# D1H.pdf register map
Vendor: Allwinner; Series: D1H.pdf; File version: 0.1
CPU: XuanTie C906 RISC-V CPU 0, little endian, MPU, FPU, double-precision FPU, 0 interrupt priority bits
Registers are 32-bit, read-write, reset 0x0 unless marked. A register's access mark holds for its fields unless they carry their own. Offsets are from the block's base; [hi:lo] are bit positions; lines under a group give offsets from that group; {n}, {i} and the like mark numbered series; 'fields as' and 'values as' point back to an identical list.

## TVD0
Base 0x05C01000
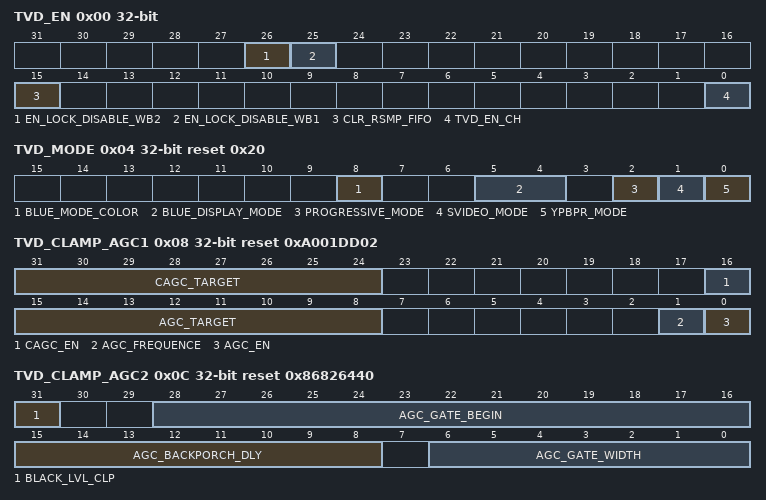
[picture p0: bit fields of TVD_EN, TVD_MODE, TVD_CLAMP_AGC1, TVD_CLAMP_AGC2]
0x00 TVD_EN — TVD MODULE CONTROL Register
  [26] EN_LOCK_DISABLE_WB2 — Enable Lock Disable WB2
  [25] EN_LOCK_DISABLE_WB1 — Enable Lock Disable WB1
  [15] CLR_RSMP_FIFO — Clear Resample FIFO 0: Release 1: Clear Set 0x1 then 0x0 to reset resample FIFO.
    0=Release; 1=Clear Set 0x1 then 0x0 to reset resample FIFO
  [0] TVD_EN_CH — TVD Enable CH 0: Disable 1: Enable
    0=Disable; 1=Enable
0x04 TVD_MODE reset 0x20 — TVD MODE CONTROL Register
  [8] BLUE_MODE_COLOR — Blue Mode Color 0: Blue 1: Black
    0=Blue; 1=Black
  [5:4] BLUE_DISPLAY_MODE — Blue Display Mode 00 : Disabled 01 : Enabled 10 : Auto 11 : Reserved
  [2] PROGRESSIVE_MODE — Progressive Mode 0: Interlace mode 1: Progressive mode
    0=Interlace_mode; 1=Progressive_mode
  [1] SVIDEO_MODE — Svideo Mode 0 : CVBS 1 : S-Video
  [0] YPBPR_MODE — Ypbpr Mode 0 : Disable the component input 1 : Enable the component input
0x08 TVD_CLAMP_AGC1 reset 0xA001DD02 — TVD CLAMP & AGC CONTROL Register1
  [31:24] CAGC_TARGET — Cagc Target These bits set the chroma AGC target
  [16] CAGC_EN — Cagc Enable 0 : OFF 1 : ON
  [15:8] AGC_TARGET — Auto Gain Control Target When AGC_EN = 1 , the AGC_TARGET is used to directly digital AGC circuit. When AGC_EN = 0 , the AGC_TARGET is used to directly drive the analog PGA. (64 represents 1x, 32 represents 0.5x).
  [1] AGC_FREQUENCE — Auto Gain Control Freqence 0 : AGC gain update once per line 1 : AGC gain update once per frame
  [0] AGC_EN — Auto Gain Control Enable 0 : AGC disable 1 : AGC enable
0x0C TVD_CLAMP_AGC2 reset 0x86826440 — TVD CLAMP & AGC CONTROL Register2
  [31] BLACK_LVL_CLP — Black Level Clamp 0: subtraction 0 1: subtraction 16
    0=subtraction_0; 1=subtraction_16
  [28:16] AGC_GATE_BEGIN — AGC Gate Begin Count from hsync to the next line AGC gate
  [15:8] AGC_BACKPORCH_DLY — AGC Backporch Delay Count from sync tip to back porch gate
  [6:0] AGC_GATE_WIDTH
0x10 TVD_HLOCK1 reset 0x20000000 — TVD HLOCK CONTROL Register1
  [31:0] H_SAMPLE_STEP — H Sample Step H_SAMPLE_STEP = Fout/Fin X 2^30
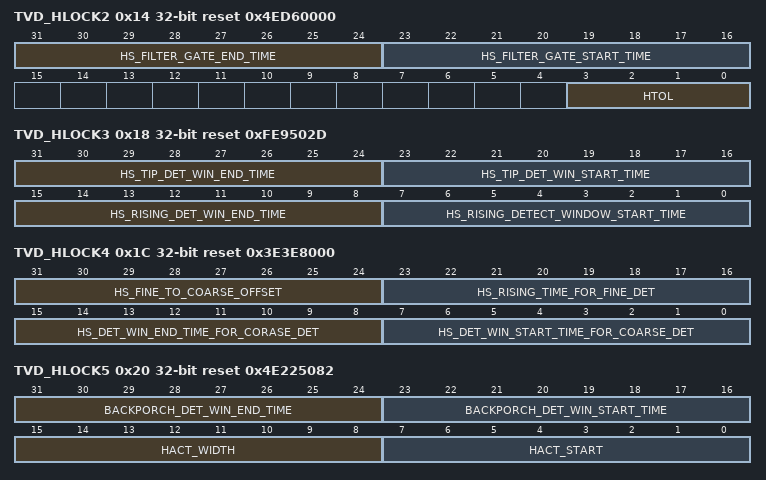
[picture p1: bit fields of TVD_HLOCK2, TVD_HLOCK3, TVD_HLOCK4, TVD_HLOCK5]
0x14 TVD_HLOCK2 reset 0x4ED60000 — TVD HLOCK CONTROL Register2
  [31:24] HS_FILTER_GATE_END_TIME — HSYNC Filter Gate End Time These bits specify the end of the horizontal-blank-interval window. Default/Hex = 78
  [23:16] HS_FILTER_GATE_START_TIME — HSYNC Filter Gate Start Time These bits specify the beginning of the horizontal-blank-interval window. Default/Hex = -42
  [3:0] HTOL — Horizontal Total Pixels Per Line 0: 858 1: 864 2~7: Reserved
0x18 TVD_HLOCK3 reset 0xFE9502D — TVD HLOCK CONTROL Register3
  [31:24] HS_TIP_DET_WIN_END_TIME — HSYNC Tip Detect Window End Time
  [23:16] HS_TIP_DET_WIN_START_TIME — HSYNC Tip Detect Window Start Time
  [15:8] HS_RISING_DET_WIN_END_TIME — HSYNC Rising Detect Window End Time
  [7:0] HS_RISING_DETECT_WINDOW_START_TIME — HSYNC Rising Detect Window Start Time
0x1C TVD_HLOCK4 reset 0x3E3E8000 — TVD HLOCK CONTROL Register4
  [31:24] HS_FINE_TO_COARSE_OFFSET — HSYNC Fine To Coarse Offset
  [23:16] HS_RISING_TIME_FOR_FINE_DET — HSYNC Rising Time For Fine Detect
  [15:8] HS_DET_WIN_END_TIME_FOR_CORASE_DET — HSYNC Detect Window End Time For Corase Detect
  [7:0] HS_DET_WIN_START_TIME_FOR_COARSE_DET — HSYNC Detect Window Start Time For Coarse Detect
0x20 TVD_HLOCK5 reset 0x4E225082 — TVD HLOCK CONTROL Register5
  [31:24] BACKPORCH_DET_WIN_END_TIME — Backporch Detect Window End Time
  [23:16] BACKPORCH_DET_WIN_START_TIME — Backporch Detect Window Start Time
  [15:8] HACT_WIDTH — Hactive Width
  [7:0] HACT_START — Hactive Start
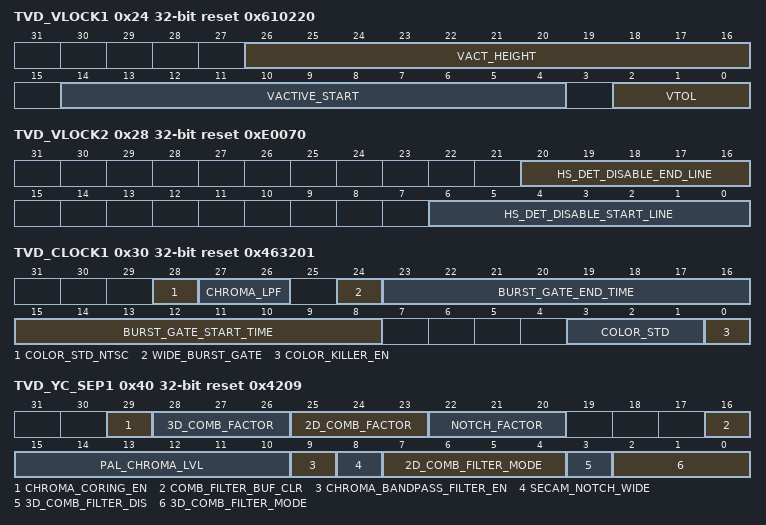
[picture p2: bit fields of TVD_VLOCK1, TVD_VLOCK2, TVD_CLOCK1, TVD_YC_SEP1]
0x24 TVD_VLOCK1 reset 0x610220 — TVD VLOCK CONTROL Register1
  [26:16] VACT_HEIGHT — Vactive Height
  [14:4] VACTIVE_START — VACT START
  [2:0] VTOL — Vertical Total Line Per Frame 0 : 525 line 1 : 625 line
0x28 TVD_VLOCK2 reset 0xE0070 — TVD VLOCK CONTROL Register2
  [20:16] HS_DET_DISABLE_END_LINE — Hsync Detector Disable End Line
  [6:0] HS_DET_DISABLE_START_LINE — Hsync Dectector Disable Start Line
0x30 TVD_CLOCK1 reset 0x463201 — TVD CHROMA LOCK CONTROL Register1
  [28] COLOR_STD_NTSC — Color Standard Ntsc 0: NTSC358 1: NTSC443 Only valid when COLOR_STD set as NTSC
    0=NTSC358; 1=NTSC443 (NTSC443 Only valid when COLOR_STD set as NTSC)
  [27:26] CHROMA_LPF — CHROMA Low Pass Filter 00: Narrow 01: Middle 10: Wide 11: Reserved
    0=Narrow; 1=Middle; 2=Wide
  [24] WIDE_BURST_GATE — Wide Burst_Gate 0: Narrow burst gate 1: Wide burst gate
    0=Narrow burst gate; 1=Wide burst gate
  [23:16] BURST_GATE_END_TIME
  [15:8] BURST_GATE_START_TIME
  [3:1] COLOR_STD — COLOR Standard 000: NTSC 001: PAL (I,B,G,H,D,N) 010: PAL (M) 011: PAL (CN) 100: SECAM
  [0] COLOR_KILLER_EN — Color Killer Enable 1: Disable color when chroma unlock
    1=Disable color when chroma unlock
0x34 TVD_CLOCK2 reset 0x21F07C1F — TVD CHROMA LOCK CONTROL Register2
  [31:0] C_SAMPLE_STEP — C Sample Step C_SAMPLE_STEP = Fsc/Fin X 2^30
0x40 TVD_YC_SEP1 reset 0x4209 — TVD YC SEPERATION CONROL Register1
  [29] CHROMA_CORING_EN — Chroma Coring Enable
  [28:26] 3D_COMB_FACTOR
  [25:23] 2D_COMB_FACTOR
  [22:20] NOTCH_FACTOR
  [16] COMB_FILTER_BUF_CLR — Comb Filter Buffer Clear 0: Not clear 1: Clear
    0=Not_clear; 1=Clear
  [15:10] PAL_CHROMA_LVL — PAL Chroma Level Chroma level threshold for chroma comb filter select
  [9] CHROMA_BANDPASS_FILTER_EN — Chroma Bandpass Filter Enable 0: Disable 1: Enable
    0=Disable; 1=Enable
  [8] SECAM_NOTCH_WIDE — Notch bandwidth 0 : Narrow 1 : Wide
  [7:4] 2D_COMB_FILTER_MODE — 2D Comb Filter Mode For NTSC: 0000: 2D comb 0001~0010: Reserved 0011: 1D comb 0100~1000: Reserved For PAL: 0000:2D comb filter1 0001: 1D comb filter1 0010: 2D comb filter2 0011: 1D comb filter2 0100: 1D comb filter3 0101: Reserved 0110: 2D comb filter3 0111~1000:Reserved
    0=_2D_comb_0001_tilde_0010 (2D comb 0001~0010: Reserved); 3=_1D_comb_0100_tilde_1000 (1D comb 0100~1000: Reserved For PAL: 0000:2D comb filter1); 1=_1D_comb_filter1; 2=_2D_comb_filter2; 3=_1D_comb_filter2; 4=_1D_comb_filter3; 6=2D comb filter3 0111~1000:Reserved
  [3] 3D_COMB_FILTER_DIS — 3D Comb Filter Disable 0: Enable 3D comb filter 1: Disable 3D comb filter
    0=Enable 3D comb filter; 1=Disable 3D comb filter
  [2:0] 3D_COMB_FILTER_MODE — 3D Comb_Filter Mode 000: 2D mode 001: 3D YC separation mode1 010~011: reserved 0100: 3D YC separation mode2
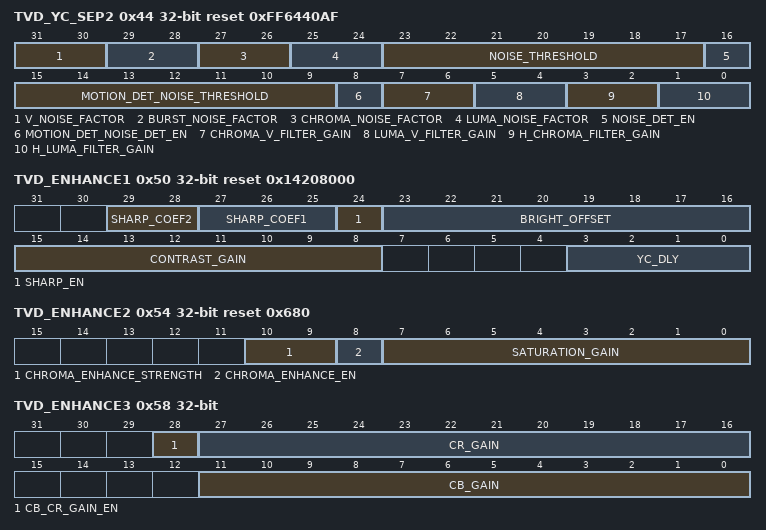
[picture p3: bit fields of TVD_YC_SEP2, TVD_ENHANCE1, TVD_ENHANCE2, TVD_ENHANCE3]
0x44 TVD_YC_SEP2 reset 0xFF6440AF — TVD YC SEPERATION CONROL Register2
  [31:30] V_NOISE_FACTOR — Vertical Noise Factor
  [29:28] BURST_NOISE_FACTOR
  [27:26] CHROMA_NOISE_FACTOR
  [25:24] LUMA_NOISE_FACTOR
  [23:17] NOISE_THRESHOLD
  [16] NOISE_DET_EN — Noise Detect Enable
  [15:9] MOTION_DET_NOISE_THRESHOLD — Motion Detect Noise Threshold
  [8] MOTION_DET_NOISE_DET_EN — Motion Detect Noise Detect Enable
  [7:6] CHROMA_V_FILTER_GAIN — Chroma Vertical Filter Gain
  [5:4] LUMA_V_FILTER_GAIN — Luma Vertical Filter Gain
  [3:2] H_CHROMA_FILTER_GAIN — Horizontal Chroma Filter Gain
  [1:0] H_LUMA_FILTER_GAIN — Horizontal Luma Filter Gain
0x50 TVD_ENHANCE1 reset 0x14208000 — TVD ENHANCEMENT CONTROL Register1
  [29:28] SHARP_COEF2
  [27:25] SHARP_COEF1 — Sharp Coef1 Ysharp = Y + YH *(SHARP_COEF1/ SHARP_COEF2)
  [24] SHARP_EN — Sharp Enable 0: Disable 1: Enable
    0=Disable; 1=Enable
  [23:16] BRIGHT_OFFSET — Bright Offset Set 0x00, brightness offset is -32; Set 0x20, brightness offset is 0. Set 0xFF, brightness offset is max.
  [15:8] CONTRAST_GAIN — Contrast Gain Set 0x00, contrast gain is min ; Set 0x80, contrast gain is 1. Set 0xFF, contrast gain is max.
  [3:0] YC_DLY — YC Delay 0000: Y and C no delay 0001: Y delay 1 cycle to C 0010: Y delay 2 cycle to C 0011: Y delay 3 cycle to C 0100: Y delay 4 cycle to C 0101: Y delay 5 cycle to C 0110: Y delay 6 cycle to C 0111: Y delay 7 cycle to C 1000: Reserved 1001: Reserved 1010: Reserved 1011: C delay 5 cycle to Y 1100: C delay 4 cycle to Y 1101: C delay 3 cycle to Y 1110: C delay 2 cycle to Y 1111: C delay 1 cycle to Y
    0=Y and C no delay; {v}=Y delay {v} cycle to C (v=1..7); 11=C delay 5 cycle to Y; 12=C delay 4 cycle to Y; 13=C delay 3 cycle to Y; 14=C delay 2 cycle to Y; 15=C delay 1 cycle to Y
0x54 TVD_ENHANCE2 reset 0x680 — TVD ENHANCEMENT CONTROL Register2
  [10:9] CHROMA_ENHANCE_STRENGTH — Chroma Enhance Strength 00: Mild 01: Low 10: Middle 11: High
    0=Mild; 1=Low; 2=Middle; 3=High
  [8] CHROMA_ENHANCE_EN — Chroma Enhance Enable 0: Disable 1: Enable
    0=Disable; 1=Enable
  [7:0] SATURATION_GAIN — Saturation Gain Set 0x00, saturation gain is min ; Set 0x80, saturation gain is 1. Set 0xFF, saturation gain is max.
0x58 TVD_ENHANCE3 — TVD ENHANCEMENT CONTROL Register3
  [28] CB_CR_GAIN_EN — Cb Cr Gain Enable
  [27:16] CR_GAIN
  [11:0] CB_GAIN
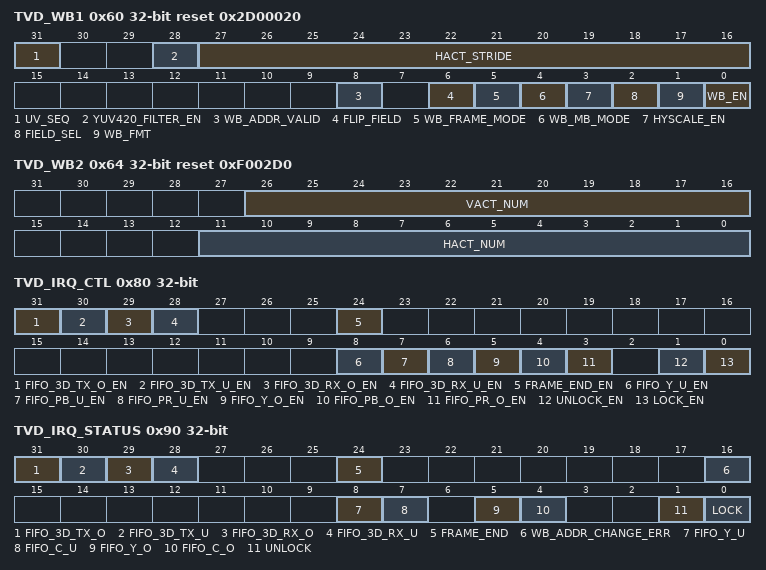
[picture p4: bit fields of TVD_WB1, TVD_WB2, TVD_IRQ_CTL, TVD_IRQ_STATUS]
0x60 TVD_WB1 reset 0x2D00020 — TVD WB DMA CONTROL Register1
  [31] UV_SEQ — UV Sequence 0: UVUV 1: VUVU
    0=UVUV; 1=VUVU
  [28] YUV420_FILTER_EN — YUV420 Filter Enable 0: disable YUV420 WB data from YUV422 without chroma filter 1: enable YUV420 WB data from YUV422 with chroma filter
    0=disable YUV420 WB data from YUV422 without chroma filter; 1=enable YUV420 WB data from YUV422 with chroma filter
  [27:16] HACT_STRIDE — Hactive Stride Horizontal active line stride
  [8] WB_ADDR_VALID — WB Address Valid 0: Invalid 1: Valid
    0=Invalid; 1=Valid
  [6] FLIP_FIELD — Flip Field This bit flips even/odd fields
  [5] WB_FRAME_MODE — WB Frame Mode 0: Odd field or even field (decided by bit2) 1: Frame
    0=Odd (Odd field or even field (decided by bit2)); 1=Frame
  [4] WB_MB_MODE — WB MB Mode 0: Planar mode 1: Mb mode
    0=Planar_mode; 1=Mb_mode
  [3] HYSCALE_EN — Hyscale_Enable
  [2] FIELD_SEL — Field_Select 0: field 0 only 1: filed 1 only
    0=field 0 only; 1=filed 1 only
  [1] WB_FMT — WB Format 0: YUV420 1: YUV422
    0=YUV420; 1=YUV422
  [0] WB_EN — WB Enable 0: Disable 1: Enable
    0=Disable; 1=Enable
0x64 TVD_WB2 reset 0xF002D0 — TVD WB DMA CONTROL Register2
  [26:16] VACT_NUM — Vertical active line number
  [11:0] HACT_NUM — Horizontal active pixel number
0x68 TVD_WB3 — TVD WB DMA CONTROL Register3
  [31:0] CH1_Y_ADDR — Ch1 Y Address
0x6C TVD_WB4 — TVD WB DMA CONTROL Register4
  [31:0] CH1_C_ADDR — Ch1 C Address
0x80 TVD_IRQ_CTL — TVD DMA Interrupt Control Register
  [all] fields
    0=IRQ_disable; 1=IRQ_enable
  [31] FIFO_3D_TX_O_EN — FIFO 3D TX Overflow Enable 0: IRQ disable 1: IRQ enable
  [30] FIFO_3D_TX_U_EN — FIFO 3D TX Underflow Enable 0: IRQ disable 1: IRQ enable
  [29] FIFO_3D_RX_O_EN — FIFO 3D RX Overflow ENable 0: IRQ disable 1: IRQ enable
  [28] FIFO_3D_RX_U_EN — FIFO 3D RX Underflow Enable 0: IRQ disable 1: IRQ enable
  [24] FRAME_END_EN — Frame End Enable 0: IRQ disable 1: IRQ enable
  [8] FIFO_Y_U_EN — FIFO Y Underflow Enable 0: IRQ disable 1: IRQ enable
  [7] FIFO_PB_U_EN — FIFO PB Underflow ENable 0: IRQ disable 1: IRQ enable
  [6] FIFO_PR_U_EN — FIFO PR Underflow Enable 0: IRQ disable 1: IRQ enable
  [5] FIFO_Y_O_EN — FIFO Y Overflow Enable 0: IRQ disable 1: IRQ enable
  [4] FIFO_PB_O_EN — FIFO PB Overflow Enable 0: IRQ disable 1: IRQ enable
  [3] FIFO_PR_O_EN — FIFO PR Overflow Enable 0: IRQ disable 1: IRQ enable
  [1] UNLOCK_EN — Unlock Enable 0: IRQ disable 1: IRQ enable
  [0] LOCK_EN — Lock Enable 0: IRQ disable 1: IRQ enable
0x90 TVD_IRQ_STATUS — TVD DMA Interrupt Status Register
  [31] FIFO_3D_TX_O — FIFO 3D TX Overflow 0: FIFO work normal 1: FIFO overflow Write 0x1 to clear this bit.
    0=FIFO work normal; 1=FIFO overflow Write 0x1 to clear this bit
  [30] FIFO_3D_TX_U — FIFO 3D TX Underflow 0: FIFO work normal 1: FIFO underflow Write 0x1 to clear this bit.
    0=FIFO work normal; 1=FIFO underflow Write 0x1 to clear this bit
  [29] FIFO_3D_RX_O — FIFO 3D RX Overflow 0: FIFO work normal 1: FIFO overflow Write 0x1 to clear this bit.
    values as FIFO_3D_TX_O
  [28] FIFO_3D_RX_U — FIFO 3D RX Underflow 0: FIFO work normal 1: FIFO underflow Write 0x1 to clear this bit.
    values as FIFO_3D_TX_U
  [24] FRAME_END — Frame End This bit is auto set every write back frame. Set 0x1 to clear this bit.
  [16] WB_ADDR_CHANGE_ERR — WB Address Change_Error Write back address change error
  [8] FIFO_Y_U — FIFO Y Underflow 0: FIFO work normal 1: FIFO underflow Write 0x1 to clear this bit.
    values as FIFO_3D_TX_U
  [7] FIFO_C_U — FIFO C Underflow 0: FIFO work normal 1: FIFO underflow Write 0x1 to clear this bit.
    values as FIFO_3D_TX_U
  [5] FIFO_Y_O — FIFO Y Overflow 0: FIFO work normal 1: FIFO overflow Write 0x1 to clear this bit.
    values as FIFO_3D_TX_O
  [4] FIFO_C_O — FIFO C Overflow 0: FIFO work normal 1: FIFO overflow Write 0x1 to clear this bit.
    values as FIFO_3D_TX_O
  [1] UNLOCK — Unlock 0: TVD status no change 1: TVD status change from lock to unlock
    0=TVD_status_no_change; 1=TVD status change from lock to unlock
  [0] LOCK — Lock 0: TVD status no change 1: TVD status change from unlock to lock
    0=TVD_status_no_change; 1=TVD status change from unlock to lock
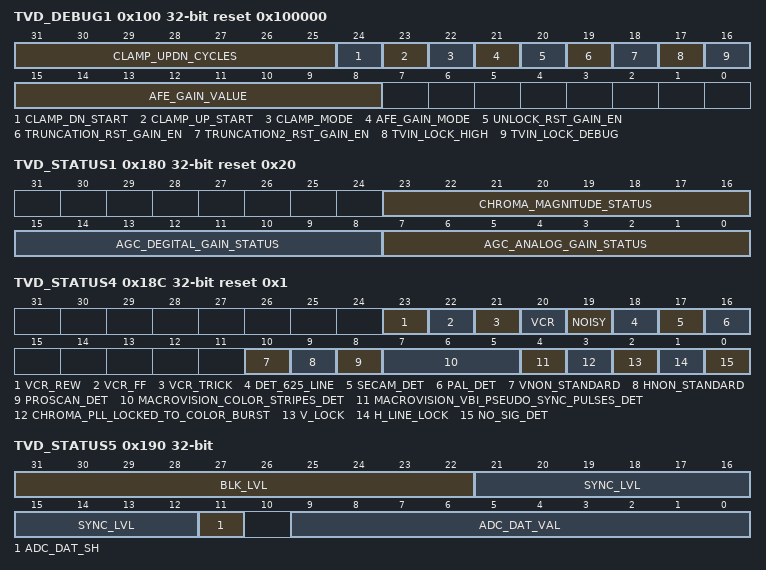
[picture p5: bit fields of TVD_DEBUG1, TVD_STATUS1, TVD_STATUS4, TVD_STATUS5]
0x100 TVD_DEBUG1 reset 0x100000 — TVD DEBUG CONTROL Register1
  [31:25] CLAMP_UPDN_CYCLES
  [24] CLAMP_DN_START — Clamp Dn Start Write 0x1 to make clamp up, clamp up value is determine by CLAMP_UPDN_CYCLES. Note that this bit is only valid when CLAMP_MODE is set as 0x1.
  [23] CLAMP_UP_START — Clamp Up Start Write 0x1 to make clamp up, clamp up value is determine by CLAMP_UPDN_CYCLES. Note that this bit is only valid when CLAMP_MODE is set as 0x1.
  [22] CLAMP_MODE — Clamp Mode 0: Normal, auto clamp control 1: Debug mode, clamp control by register
    0=Normal, auto clamp control; 1=Debug mode, clamp control by register
  [21] AFE_GAIN_MODE — Afe Gain Mode 0: Auto gain mode 1: Debug mode, AFE gain is determine by AFE_GAIN_VALUE
    0=Auto gain mode; 1=Debug mode, AFE gain is determine by AFE_GAIN_VALUE
  [20] UNLOCK_RST_GAIN_EN — Unlock Reset Gain Enable
  [19] TRUNCATION_RST_GAIN_EN — Truncation Reset Gain Enable
  [18] TRUNCATION2_RST_GAIN_EN — Truncation2 Reset Gain Enable
  [17] TVIN_LOCK_HIGH
  [16] TVIN_LOCK_DEBUG
  [15:8] AFE_GAIN_VALUE
0x180 TVD_STATUS1 reset 0x20 — TVD DEBUG STATUS Register1
  [23:16] CHROMA_MAGNITUDE_STATUS ro — These bits contain the chroma magnitude.
  [15:8] AGC_DEGITAL_GAIN_STATUS ro — These bits contain the digital AGC gain value.
  [7:0] AGC_ANALOG_GAIN_STATUS ro — These bits contain the analog AGC gain value.
0x184 TVD_STATUS2 reset 0x21F07C1F — TVD DEBUG STATUS Register2
  [31:0] CHROMA_SYNC_DTO_STATUS ro
0x188 TVD_STATUS3 reset 0x20000000 — TVD DEBUG STATUS Register3
  [29:0] H_SYNC_DTO_STS ro — Horizontal Sync Dto Status
0x18C TVD_STATUS4 reset 0x1 — TVD DEBUG STATUS Register4
  [23] VCR_REW ro — VCR Rewind Detected
  [22] VCR_FF ro — VCR Fast-Forward Detected
  [21] VCR_TRICK ro — VCR Trick-Mode Detected
  [20] VCR ro — VCR Detected
  [19] NOISY ro — Noisy Signal Detected. This bit is set when the detected noise value (status register 7Fh) is greater than the value programmed into the “noise_thresh” register (05h).
  [18] DET_625_LINE ro — Detect 625 Line 0: 525 lines 1: 625 lines
    0=525 lines; 1=625 lines
  [17] SECAM_DET ro — SECAM Colour Mode Detected
  [16] PAL_DET ro — PAL Colour Mode Detected
  [10] VNON_STANDARD ro — Vertical Frequency Non-Standard Input Signal Detected
  [9] HNON_STANDARD ro — Horizontal Frequency Non-Standard Input Signal Detected
  [8] PROSCAN_DET ro — Progressive Scan Detected
  [7:5] MACROVISION_COLOR_STRIPES_DET ro — The Number Indicates The Number Of Color Stripe lines in each group
  [4] MACROVISION_VBI_PSEUDO_SYNC_PULSES_DET ro — Macrovision Vbi Pseudo Sync Pulses Detect 0: Undetected 1: Detected
    0=Undetected; 1=Detected
  [3] CHROMA_PLL_LOCKED_TO_COLOR_BURST ro — Chroma Pll Locked To Color Burst 0: Unlock 1: Locked
    0=Unlock; 1=Locked
  [2] V_LOCK ro — Vertical Lock 0: Unlock 1: Locked
    0=Unlock; 1=Locked
  [1] H_LINE_LOCK ro — Horizontal line locked 0: Unlock 1: Locked
    0=Unlock; 1=Locked
  [0] NO_SIG_DET ro — No Signal Detected 0 : Signal Detected 1 :No Signal Detected
0x190 TVD_STATUS5 — TVD DEBUG STATUS Register5
  [31:22] BLK_LVL ro — Blank Level
  [21:12] SYNC_LVL ro — Sync Level
  [11] ADC_DAT_SH — ADC Data Show
  [9:0] ADC_DAT_VAL ro — ADC Data Value
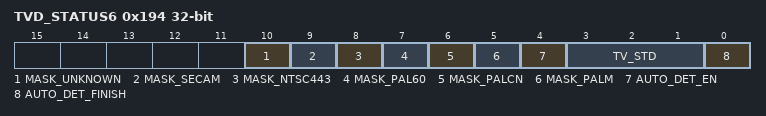
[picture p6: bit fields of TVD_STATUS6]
0x194 TVD_STATUS6 — TVD DEBUG STATUS Register6
  [10] MASK_UNKNOWN
  [9] MASK_SECAM
  [8] MASK_NTSC443
  [7] MASK_PAL60
  [6] MASK_PALCN
  [5] MASK_PALM
  [4] AUTO_DET_EN — Auto Detect Enable 0: Disable 1: Enable
    0=Disable; 1=Enable
  [3:1] TV_STD ro — TV Standard 001: V525_NTSC 010: V625_PAL 011: V525_PALM 100: V625_PALN 101: V525_PAL60 110: V525_NTSC443 111: V625_SECAM
    1=V525_NTSC; 2=V625_PAL; 3=V525_PALM; 4=V625_PALN; 5=V525_PAL60; 6=V525_NTSC443; 7=V625_SECAM
  [0] AUTO_DET_FINISH ro — Auto Detect Finish 7 Memory ................................................................................................................................................................... 584 7.1 SDRAM Controller (DRAMC) ........................................................................................................................... 584 7.2 SD/MMC Host Controller (SMHC) ................................................................................................................... 585 7.2.1 Overview ............................................................................................................................................. 585 7.2.2 Block Diagram ..................................................................................................................................... 585 7.2.3 Functional Description ........................................................................................................................ 586 7.2.4 Programming Guidelines ..................................................................................................................... 599 7.2.5 Register List ......................................................................................................................................... 604 7.2.6 Register Description ............................................................................................................................ 606 Figure 7-1 SMHC Block Diagram ....................................................................................................................................... 586 Figure 7-2 Command Token Format ................................................................................................................................. 589 Figure 7-3 Response Token Format .................................................................................................................................. 589 Figure 7-4 Data Packet Format for SDR ............................................................................................................................ 590 Figure 7-5 Data Packet Format for DDR ............................................................................................................................ 591 Figure 7-6 Data Packet Format for DDR in HS400 Mode .................................................................................................. 592 Figure 7-7 Single-Block and Multi-Block Read Operation ................................................................................................. 593 Figure 7-8 Single-Block and Multi-Block Read Operation ................................................................................................. 593 Figure 7-9 Phase Offset of Command and Data in SDR Mode .......................................................................................... 594 Figure 7-10 Phase Offset of Command and Data in DDR4 Mode (SMHC_NTSR[31] = 0) ................................................. 595 Figure 7-11 Phase Offset of Command and Data in DDR4 Mode ..................................................................................... 595 Figure 7-12 Phase Offset of Command and Data in DDR4 (2x Mode) (SMHC_NTSR[31] = 1) .......................................... 596 Figure 7-13 IDMAC Descriptor Structure Diagram ............................................................................................................ 597 Table 7-1 SMHC Sub-blocks .............................................................................................................................................. 586 Table 7-2 SMHC External Signals ....................................................................................................................................... 587 Table 7-3 SMHC0/1 Clock Sources .................................................................................................................................... 587 Table 7-4 SMHC2 Clock Sources ........................................................................................................................................ 587 Table 7-5 Speed Modes Supported by SD 3.0 ................................................................................................................... 593 Table 7-6 Speed Modes Supported by eMMC 5.0 ............................................................................................................ 594 Table 7-7 Phase Offset of Command and Data in SDR Mode ........................................................................................... 594 Table 7-8 Phase Offset of Command and Data in DDR4 (2x) Mode ................................................................................. 596 Table 7-9 DES0 Definition ................................................................................................................................................. 597 Table 7-10 DES1 Definition ............................................................................................................................................... 598 Table 7-11 DES2 Definition ............................................................................................................................................... 598 Table 7-12 DES3 Definition ............................................................................................................................................... 598 The DRAMC provides a simple, flexible, burst-optimized interface to all industy-standard DDR2/DDR3 SDRAM. It supports up to a 16 Gbits memory address space. The DRAMC automatically handles memory management, initialization, and refresh operations. It gives the host CPU a simple command interface, hiding details of the required address, page, and burst handling procedures. All memory parameters are runtime-configurable, including timing, memory setting, SDRAM type, and Extended-Mode-Register settings. The DRAMC has the following features: Supports 16-bit one channel Supports 2 Chip Select Supports DDR2/DDR3 SDRAM Maximum capacity up to 2 GB Supports clock frequency up to 533 MHz for DDR2 Supports clock frequency up to 800 MHz for DDR3
